# LM3S5762 register map
File version: 7944
Registers are 32-bit, read-write, no defined reset value unless marked. A register's access mark holds for its fields unless they carry their own. Offsets are from the block's base; [hi:lo] are bit positions; {n}, {i} and the like mark numbered series.

## SSI0 — Register map for SSI0 peripheral
Base 0x40008000; register names take the prefix SSI0
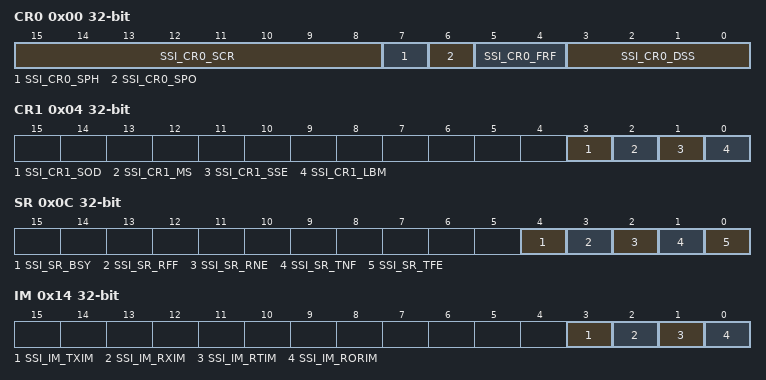
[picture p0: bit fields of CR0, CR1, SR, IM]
0x00 CR0 — SSI Control 0
  [15:8] SSI_CR0_SCR — SSI Serial Clock Rate
  [7] SSI_CR0_SPH — SSI Serial Clock Phase
  [6] SSI_CR0_SPO — SSI Serial Clock Polarity
  [5:4] SSI_CR0_FRF — SSI Frame Format Select
    0=SSI_CR0_FRF_MOTO (Freescale SPI Frame Format); 1=SSI_CR0_FRF_TI (Texas Instruments Synchronous Serial Frame Format); 2=SSI_CR0_FRF_NMW (MICROWIRE Frame Format)
  [3:0] SSI_CR0_DSS — SSI Data Size Select
    {v}={v+1}-bit data (v=3..15)
0x04 CR1 — SSI Control 1
  [3] SSI_CR1_SOD — SSI Slave Mode Output Disable
  [2] SSI_CR1_MS — SSI Master/Slave Select
  [1] SSI_CR1_SSE — SSI Synchronous Serial Port Enable
  [0] SSI_CR1_LBM — SSI Loopback Mode
0x08 DR — SSI Data
  [15:0] SSI_DR_DATA — SSI Receive/Transmit Data
0x0C SR — SSI Status
  [4] SSI_SR_BSY — SSI Busy Bit
  [3] SSI_SR_RFF — SSI Receive FIFO Full
  [2] SSI_SR_RNE — SSI Receive FIFO Not Empty
  [1] SSI_SR_TNF — SSI Transmit FIFO Not Full
  [0] SSI_SR_TFE — SSI Transmit FIFO Empty
0x10 CPSR — SSI Clock Prescale
  [7:0] SSI_CPSR_CPSDVSR — SSI Clock Prescale Divisor
0x14 IM — SSI Interrupt Mask
  [3] SSI_IM_TXIM — SSI Transmit FIFO Interrupt Mask
  [2] SSI_IM_RXIM — SSI Receive FIFO Interrupt Mask
  [1] SSI_IM_RTIM — SSI Receive Time-Out Interrupt Mask
  [0] SSI_IM_RORIM — SSI Receive Overrun Interrupt Mask
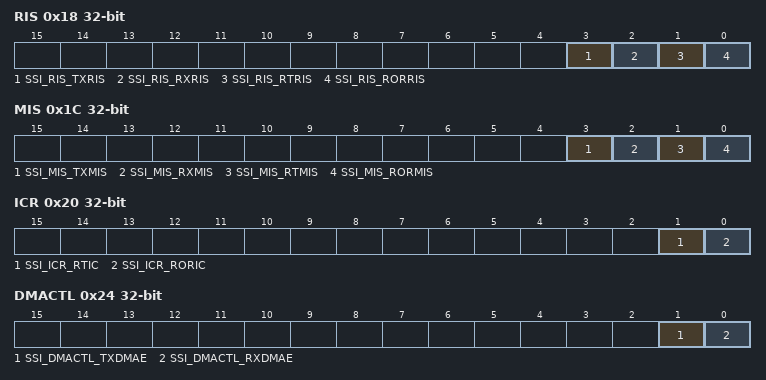
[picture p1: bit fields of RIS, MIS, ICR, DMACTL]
0x18 RIS — SSI Raw Interrupt Status
  [3] SSI_RIS_TXRIS — SSI Transmit FIFO Raw Interrupt Status
  [2] SSI_RIS_RXRIS — SSI Receive FIFO Raw Interrupt Status
  [1] SSI_RIS_RTRIS — SSI Receive Time-Out Raw Interrupt Status
  [0] SSI_RIS_RORRIS — SSI Receive Overrun Raw Interrupt Status
0x1C MIS — SSI Masked Interrupt Status
  [3] SSI_MIS_TXMIS — SSI Transmit FIFO Masked Interrupt Status
  [2] SSI_MIS_RXMIS — SSI Receive FIFO Masked Interrupt Status
  [1] SSI_MIS_RTMIS — SSI Receive Time-Out Masked Interrupt Status
  [0] SSI_MIS_RORMIS — SSI Receive Overrun Masked Interrupt Status
0x20 ICR wo — SSI Interrupt Clear
  [1] SSI_ICR_RTIC — SSI Receive Time-Out Interrupt Clear
  [0] SSI_ICR_RORIC — SSI Receive Overrun Interrupt Clear
0x24 DMACTL — SSI DMA Control
  [1] SSI_DMACTL_TXDMAE — Transmit DMA Enable
  [0] SSI_DMACTL_RXDMAE — Receive DMA Enable

## HIB — Register map for HIB peripheral
Base 0x400FC000; register names take the prefix HIB
0x00 RTCC — Hibernation RTC Counter
  [31:0] HIB_RTCC — RTC Counter
0x04 RTCM0 — Hibernation RTC Match 0
  [31:0] HIB_RTCM0 — RTC Match 0
0x08 RTCM1 — Hibernation RTC Match 1
  [31:0] HIB_RTCM1 — RTC Match 1
0x0C RTCLD — Hibernation RTC Load
  [31:0] HIB_RTCLD — RTC Load
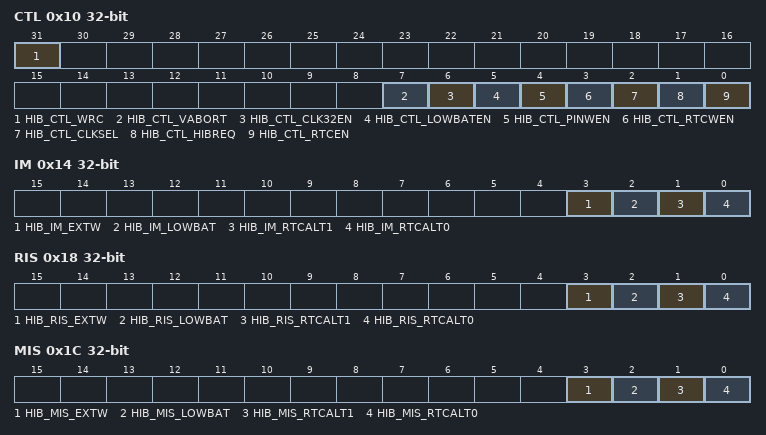
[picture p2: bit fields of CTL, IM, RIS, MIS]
0x10 CTL — Hibernation Control
  [31] HIB_CTL_WRC — Write Complete/Capable
  [7] HIB_CTL_VABORT — Power Cut Abort Enable
  [6] HIB_CTL_CLK32EN — Clocking Enable
  [5] HIB_CTL_LOWBATEN — Low Battery Monitoring Enable
  [4] HIB_CTL_PINWEN — External WAKE Pin Enable
  [3] HIB_CTL_RTCWEN — RTC Wake-up Enable
  [2] HIB_CTL_CLKSEL — Hibernation Module Clock Select
  [1] HIB_CTL_HIBREQ — Hibernation Request
  [0] HIB_CTL_RTCEN — RTC Timer Enable
0x14 IM — Hibernation Interrupt Mask
  [3] HIB_IM_EXTW — External Wake-Up Interrupt Mask
  [2] HIB_IM_LOWBAT — Low Battery Voltage Interrupt Mask
  [1] HIB_IM_RTCALT1 — RTC Alert 1 Interrupt Mask
  [0] HIB_IM_RTCALT0 — RTC Alert 0 Interrupt Mask
0x18 RIS — Hibernation Raw Interrupt Status
  [3] HIB_RIS_EXTW — External Wake-Up Raw Interrupt Status
  [2] HIB_RIS_LOWBAT — Low Battery Voltage Raw Interrupt Status
  [1] HIB_RIS_RTCALT1 — RTC Alert 1 Raw Interrupt Status
  [0] HIB_RIS_RTCALT0 — RTC Alert 0 Raw Interrupt Status
0x1C MIS — Hibernation Masked Interrupt Status
  [3] HIB_MIS_EXTW — External Wake-Up Masked Interrupt Status
  [2] HIB_MIS_LOWBAT — Low Battery Voltage Masked Interrupt Status
  [1] HIB_MIS_RTCALT1 — RTC Alert 1 Masked Interrupt Status
  [0] HIB_MIS_RTCALT0 — RTC Alert 0 Masked Interrupt Status
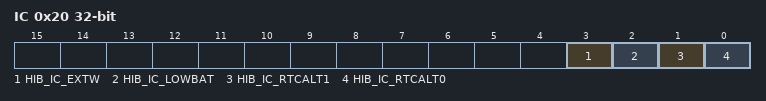
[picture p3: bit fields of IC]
0x20 IC — Hibernation Interrupt Clear
  [3] HIB_IC_EXTW — External Wake-Up Masked Interrupt Clear
  [2] HIB_IC_LOWBAT — Low Battery Voltage Masked Interrupt Clear
  [1] HIB_IC_RTCALT1 — RTC Alert1 Masked Interrupt Clear
  [0] HIB_IC_RTCALT0 — RTC Alert0 Masked Interrupt Clear
0x24 RTCT — Hibernation RTC Trim
  [15:0] HIB_RTCT_TRIM — RTC Trim Value
0x30 DATA — Hibernation Data
  [31:0] HIB_DATA_RTD — Hibernation Module NV Data
